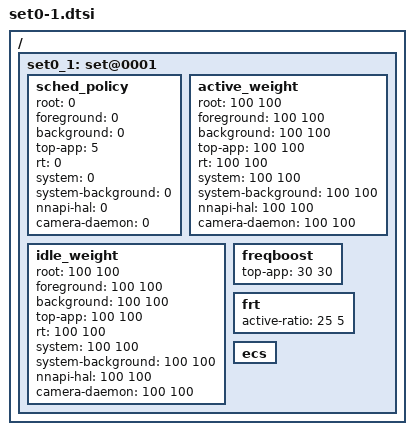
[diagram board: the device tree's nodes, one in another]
/ {
	/* normal mode - touch boost */
	set0_1: set@0001 {
		sched_policy {
			root = <0>;
			foreground = <0>;
			background = <0>;
			top-app = <5>;
			rt = <0>;
			system = <0>;
			system-background = <0>;
			nnapi-hal = <0>;
			camera-daemon = <0>;
		};

		active_weight {
			root = <100 100>;
			foreground = <100 100>;
			background = <100 100>;
			top-app = <100 100>;
			rt = <100 100>;
			system = <100 100>;
			system-background = <100 100>;
			nnapi-hal = <100 100>;
			camera-daemon = <100 100>;
		};

		idle_weight {
			root = <100 100>;
			foreground = <100 100>;
			background = <100 100>;
			top-app = <100 100>;
			rt = <100 100>;
			system = <100 100>;
			system-background = <100 100>;
			nnapi-hal = <100 100>;
			camera-daemon = <100 100>;
		};

		/* Boosting margin applied to frequency selection */
		freqboost {			/* LIT BIG */
			top-app			= < 30  30>;
		};

		frt {	   			/* LIT BIG */
			active-ratio 		= < 25   5>;
		};

		ecs { };
	};
};
